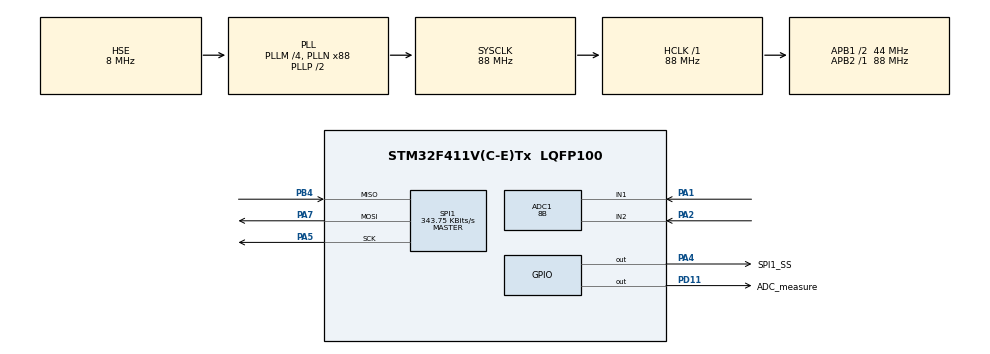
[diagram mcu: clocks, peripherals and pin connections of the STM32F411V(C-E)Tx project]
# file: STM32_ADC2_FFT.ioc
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ADC1.Channel-0\#ChannelRegularConversion=ADC_CHANNEL_1
ADC1.Channel-1\#ChannelRegularConversion=ADC_CHANNEL_2
ADC1.ClockPrescaler=ADC_CLOCK_SYNC_PCLK_DIV4
ADC1.ContinuousConvMode=ENABLE
ADC1.DMAContinuousRequests=ENABLE
ADC1.EOCSelection=ADC_EOC_SINGLE_CONV
ADC1.EnableAnalogWatchDog=true
ADC1.HighThreshold=128
ADC1.ITMode=ENABLE
ADC1.NbrOfConversion=2
ADC1.NbrOfConversionFlag=1
ADC1.Rank-0\#ChannelRegularConversion=1
ADC1.Rank-1\#ChannelRegularConversion=2
ADC1.Resolution=ADC_RESOLUTION_8B
ADC1.SamplingTime-0\#ChannelRegularConversion=ADC_SAMPLETIME_3CYCLES
ADC1.SamplingTime-1\#ChannelRegularConversion=ADC_SAMPLETIME_3CYCLES
ADC1.ScanConvMode=ENABLE
ADC1.WatchdogChannel=ADC_CHANNEL_1
ADC1.master=1
Dma.ADC1.0.Direction=DMA_PERIPH_TO_MEMORY
Dma.ADC1.0.FIFOMode=DMA_FIFOMODE_DISABLE
Dma.ADC1.0.Instance=DMA2_Stream0
Dma.ADC1.0.MemDataAlignment=DMA_MDATAALIGN_BYTE
Dma.ADC1.0.MemInc=DMA_MINC_ENABLE
Dma.ADC1.0.Mode=DMA_CIRCULAR
Dma.ADC1.0.PeriphDataAlignment=DMA_PDATAALIGN_BYTE
Dma.ADC1.0.PeriphInc=DMA_PINC_DISABLE
Dma.ADC1.0.Priority=DMA_PRIORITY_VERY_HIGH
Dma.Request0=ADC1
Mcu.Family=STM32F4
Mcu.Name=STM32F411V(C-E)Tx
Mcu.Package=LQFP100
NVIC.ADC_IRQn=true\:0\:0\:false\:false\:true\:true\:true\:true
NVIC.DMA2_Stream0_IRQn=true\:1\:0\:true\:false\:true\:false\:true\:true
NVIC.PriorityGroup=NVIC_PRIORITYGROUP_1
NVIC.SPI1_IRQn=true\:1\:0\:true\:false\:true\:true\:true\:true
NVIC.TIM1_BRK_TIM9_IRQn=true\:1\:0\:true\:false\:true\:true\:true\:true
PA1.Signal=ADCx_IN1
PA13.Mode=Serial_Wire
PA13.Signal=SYS_JTMS-SWDIO
PA14.Mode=Serial_Wire
PA14.Signal=SYS_JTCK-SWCLK
PA2.Signal=ADCx_IN2
PA4.GPIO_Label=SPI1_SS
PA4.GPIO_Speed=GPIO_SPEED_FREQ_VERY_HIGH
PA4.PinState=GPIO_PIN_SET
PA4.Signal=GPIO_Output
PA5.Mode=Full_Duplex_Master
PA5.Signal=SPI1_SCK
PA7.Mode=Full_Duplex_Master
PA7.Signal=SPI1_MOSI
PB4.Mode=Full_Duplex_Master
PB4.Signal=SPI1_MISO
PD11.GPIO_Label=ADC_measure
PD11.GPIO_Speed=GPIO_SPEED_FREQ_VERY_HIGH
PD11.Signal=GPIO_Output
PH0\ -\ OSC_IN.Mode=HSE-External-Oscillator
PH0\ -\ OSC_IN.Signal=RCC_OSC_IN
PH1\ -\ OSC_OUT.Mode=HSE-External-Oscillator
PH1\ -\ OSC_OUT.Signal=RCC_OSC_OUT
ProjectManager.HeapSize=0x200
ProjectManager.StackSize=0x400
ProjectManager.TargetToolchain=STM32CubeIDE
RCC.48MHZClocksFreq_Value=58666666.666666664
RCC.AHBFreq_Value=88000000
RCC.APB1CLKDivider=RCC_HCLK_DIV2
RCC.APB1Freq_Value=44000000
RCC.APB1TimFreq_Value=88000000
RCC.APB2Freq_Value=88000000
RCC.APB2TimFreq_Value=88000000
RCC.CortexFreq_Value=88000000
RCC.HCLKFreq_Value=88000000
RCC.HSE_VALUE=8000000
RCC.HSI_VALUE=16000000
RCC.LSE_VALUE=32768
RCC.PLLI2SM=5
RCC.PLLI2SN=200
RCC.PLLM=4
RCC.PLLN=88
RCC.PLLQ=3
RCC.PLLSourceVirtual=RCC_PLLSOURCE_HSE
RCC.SYSCLKFreq_VALUE=88000000
RCC.SYSCLKSource=RCC_SYSCLKSOURCE_PLLCLK
RCC.VCOOutputFreq_Value=176000000
SH.ADCx_IN1.0=ADC1_IN1,IN1
SH.ADCx_IN2.0=ADC1_IN2,IN2
SPI1.BaudRatePrescaler=SPI_BAUDRATEPRESCALER_256
SPI1.CLKPhase=SPI_PHASE_2EDGE
SPI1.CalculateBaudRate=343.75 KBits/s
SPI1.Direction=SPI_DIRECTION_2LINES
SPI1.Mode=SPI_MODE_MASTER
SPI1.VirtualType=VM_MASTER
STMicroelectronics.X-CUBE-ALGOBUILD.1.3.0.LibraryCcDSPOoLibraryJjDSPOoLibrary=true
TIM9.Period=60000 -1
TIM9.Prescaler=320 - 1
VP_STMicroelectronics.X-CUBE-ALGOBUILD_VS_DSPOoLibraryJjLibrary_1.3.0_1.3.0.Mode=DSPOoLibraryJjLibrary
VP_TIM9_VS_ClockSourceINT.Mode=Internal
board=STM32F411E-DISCO

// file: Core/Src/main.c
/* USER CODE BEGIN Header */
/**
  ******************************************************************************
  * @file           : main.c
  * @brief          : Main program body
  ******************************************************************************
  * @attention
  *
  * Copyright (c) 2023 STMicroelectronics.
  * All rights reserved.
  *
  * This software is licensed under terms that can be found in the LICENSE file
  * in the root directory of this software component.
  * If no LICENSE file comes with this software, it is provided AS-IS.
  *
  ******************************************************************************
  */
/* USER CODE END Header */
#include "main.h"

/* USER CODE BEGIN Includes */

#include "processing.h"
#include "settings.h"
#include "arm_math.h"
/* USER CODE END Includes */

ADC_HandleTypeDef hadc1;
DMA_HandleTypeDef hdma_adc1;

SPI_HandleTypeDef hspi1;

TIM_HandleTypeDef htim9;

/* USER CODE BEGIN PV */

volatile uint8_t ADC_DMA_Buf[DMA_BUFFER_SIZE];
volatile uint8_t processReadyFlag = 0;

/* USER CODE END PV */

void DoFFT();
void SystemClock_Config(void);
static void MX_GPIO_Init(void);
static void MX_DMA_Init(void);
static void MX_ADC1_Init(void);
static void MX_SPI1_Init(void);
static void MX_TIM9_Init(void);

int main(void)
{

  /* MCU Configuration--------------------------------------------------------*/

  /* Reset of all peripherals, Initializes the Flash interface and the Systick. */
  HAL_Init();

  /* Configure the system clock */
  SystemClock_Config();

  /* Initialize all configured peripherals */
  MX_GPIO_Init();
  MX_DMA_Init();
  MX_ADC1_Init();
  MX_SPI1_Init();
  MX_TIM9_Init();
  /* USER CODE BEGIN 2 */

  //Start the timer
  //HAL_TIM_Base_Start_IT(&htim9);
  set_trigger_channel(1);
  set_trigger(&hadc1, RISING_EDGE, 50);
  update_settings();
  HAL_ADC_Start_DMA(&hadc1, ADC_DMA_Buf, DMA_BUFFER_SIZE);

  /* USER CODE END 2 */

  /* Infinite loop */
  /* USER CODE BEGIN WHILE */
  while (1)
  {

	 //if (processReadyFlag)
	 {
		  process_DMA_buf();
	 }

    /* USER CODE END WHILE */

  }
}

void SystemClock_Config(void)
{
  RCC_OscInitTypeDef RCC_OscInitStruct = {0};
  RCC_ClkInitTypeDef RCC_ClkInitStruct = {0};

  /** Configure the main internal regulator output voltage
  */
  __HAL_RCC_PWR_CLK_ENABLE();
  __HAL_PWR_VOLTAGESCALING_CONFIG(PWR_REGULATOR_VOLTAGE_SCALE1);

  /** Initializes the RCC Oscillators according to the specified parameters
  * in the RCC_OscInitTypeDef structure.
  */
  RCC_OscInitStruct.OscillatorType = RCC_OSCILLATORTYPE_HSE;
  RCC_OscInitStruct.HSEState = RCC_HSE_ON;
  RCC_OscInitStruct.PLL.PLLState = RCC_PLL_ON;
  RCC_OscInitStruct.PLL.PLLSource = RCC_PLLSOURCE_HSE;
  RCC_OscInitStruct.PLL.PLLM = 4;
  RCC_OscInitStruct.PLL.PLLN = 88;
  RCC_OscInitStruct.PLL.PLLP = RCC_PLLP_DIV2;
  RCC_OscInitStruct.PLL.PLLQ = 3;
  if (HAL_RCC_OscConfig(&RCC_OscInitStruct) != HAL_OK)
  {
    Error_Handler();
  }

  /** Initializes the CPU, AHB and APB buses clocks
  */
  RCC_ClkInitStruct.ClockType = RCC_CLOCKTYPE_HCLK|RCC_CLOCKTYPE_SYSCLK
                              |RCC_CLOCKTYPE_PCLK1|RCC_CLOCKTYPE_PCLK2;
  RCC_ClkInitStruct.SYSCLKSource = RCC_SYSCLKSOURCE_PLLCLK;
  RCC_ClkInitStruct.AHBCLKDivider = RCC_SYSCLK_DIV1;
  RCC_ClkInitStruct.APB1CLKDivider = RCC_HCLK_DIV2;
  RCC_ClkInitStruct.APB2CLKDivider = RCC_HCLK_DIV1;

  if (HAL_RCC_ClockConfig(&RCC_ClkInitStruct, FLASH_LATENCY_2) != HAL_OK)
  {
    Error_Handler();
  }
}

static void MX_ADC1_Init(void)
{

  ADC_AnalogWDGConfTypeDef AnalogWDGConfig = {0};
  ADC_ChannelConfTypeDef sConfig = {0};

  /** Configure the global features of the ADC (Clock, Resolution, Data Alignment and number of conversion)
  */
  hadc1.Instance = ADC1;
  hadc1.Init.ClockPrescaler = ADC_CLOCK_SYNC_PCLK_DIV4;
  hadc1.Init.Resolution = ADC_RESOLUTION_8B;
  hadc1.Init.ScanConvMode = ENABLE;
  hadc1.Init.ContinuousConvMode = ENABLE;
  hadc1.Init.DiscontinuousConvMode = DISABLE;
  hadc1.Init.ExternalTrigConvEdge = ADC_EXTERNALTRIGCONVEDGE_NONE;
  hadc1.Init.ExternalTrigConv = ADC_SOFTWARE_START;
  hadc1.Init.DataAlign = ADC_DATAALIGN_RIGHT;
  hadc1.Init.NbrOfConversion = 2;
  hadc1.Init.DMAContinuousRequests = ENABLE;
  hadc1.Init.EOCSelection = ADC_EOC_SINGLE_CONV;
  if (HAL_ADC_Init(&hadc1) != HAL_OK)
  {
    Error_Handler();
  }

  /** Configure the analog watchdog
  */
  AnalogWDGConfig.WatchdogMode = ADC_ANALOGWATCHDOG_SINGLE_REG;
  AnalogWDGConfig.HighThreshold = 128;
  AnalogWDGConfig.LowThreshold = 0;
  AnalogWDGConfig.Channel = ADC_CHANNEL_1;
  AnalogWDGConfig.ITMode = ENABLE;
  if (HAL_ADC_AnalogWDGConfig(&hadc1, &AnalogWDGConfig) != HAL_OK)
  {
    Error_Handler();
  }

  /** Configure for the selected ADC regular channel its corresponding rank in the sequencer and its sample time.
  */
  sConfig.Channel = ADC_CHANNEL_1;
  sConfig.Rank = 1;
  sConfig.SamplingTime = ADC_SAMPLETIME_3CYCLES;
  if (HAL_ADC_ConfigChannel(&hadc1, &sConfig) != HAL_OK)
  {
    Error_Handler();
  }

  /** Configure for the selected ADC regular channel its corresponding rank in the sequencer and its sample time.
  */
  sConfig.Channel = ADC_CHANNEL_2;
  sConfig.Rank = 2;
  if (HAL_ADC_ConfigChannel(&hadc1, &sConfig) != HAL_OK)
  {
    Error_Handler();
  }

}

static void MX_SPI1_Init(void)
{

  /* SPI1 parameter configuration*/
  hspi1.Instance = SPI1;
  hspi1.Init.Mode = SPI_MODE_MASTER;
  hspi1.Init.Direction = SPI_DIRECTION_2LINES;
  hspi1.Init.DataSize = SPI_DATASIZE_8BIT;
  hspi1.Init.CLKPolarity = SPI_POLARITY_LOW;
  hspi1.Init.CLKPhase = SPI_PHASE_2EDGE;
  hspi1.Init.NSS = SPI_NSS_SOFT;
  hspi1.Init.BaudRatePrescaler = SPI_BAUDRATEPRESCALER_256;
  hspi1.Init.FirstBit = SPI_FIRSTBIT_MSB;
  hspi1.Init.TIMode = SPI_TIMODE_DISABLE;
  hspi1.Init.CRCCalculation = SPI_CRCCALCULATION_DISABLE;
  hspi1.Init.CRCPolynomial = 10;
  if (HAL_SPI_Init(&hspi1) != HAL_OK)
  {
    Error_Handler();
  }

}

static void MX_TIM9_Init(void)
{

  TIM_ClockConfigTypeDef sClockSourceConfig = {0};

  htim9.Instance = TIM9;
  htim9.Init.Prescaler = 320 - 1;
  htim9.Init.CounterMode = TIM_COUNTERMODE_UP;
  htim9.Init.Period = 60000 -1;
  htim9.Init.ClockDivision = TIM_CLOCKDIVISION_DIV1;
  htim9.Init.AutoReloadPreload = TIM_AUTORELOAD_PRELOAD_DISABLE;
  if (HAL_TIM_Base_Init(&htim9) != HAL_OK)
  {
    Error_Handler();
  }
  sClockSourceConfig.ClockSource = TIM_CLOCKSOURCE_INTERNAL;
  if (HAL_TIM_ConfigClockSource(&htim9, &sClockSourceConfig) != HAL_OK)
  {
    Error_Handler();
  }

}

static void MX_DMA_Init(void)
{

  /* DMA controller clock enable */
  __HAL_RCC_DMA2_CLK_ENABLE();

  /* DMA interrupt init */
  /* DMA2_Stream0_IRQn interrupt configuration */
  HAL_NVIC_SetPriority(DMA2_Stream0_IRQn, 1, 0);
  HAL_NVIC_EnableIRQ(DMA2_Stream0_IRQn);

}

static void MX_GPIO_Init(void)
{
  GPIO_InitTypeDef GPIO_InitStruct = {0};

  /* GPIO Ports Clock Enable */
  __HAL_RCC_GPIOH_CLK_ENABLE();
  __HAL_RCC_GPIOA_CLK_ENABLE();
  __HAL_RCC_GPIOD_CLK_ENABLE();
  __HAL_RCC_GPIOB_CLK_ENABLE();

  /*Configure GPIO pin Output Level */
  HAL_GPIO_WritePin(SPI1_SS_GPIO_Port, SPI1_SS_Pin, GPIO_PIN_SET);

  /*Configure GPIO pin Output Level */
  HAL_GPIO_WritePin(ADC_measure_GPIO_Port, ADC_measure_Pin, GPIO_PIN_RESET);

  /*Configure GPIO pin : SPI1_SS_Pin */
  GPIO_InitStruct.Pin = SPI1_SS_Pin;
  GPIO_InitStruct.Mode = GPIO_MODE_OUTPUT_PP;
  GPIO_InitStruct.Pull = GPIO_NOPULL;
  GPIO_InitStruct.Speed = GPIO_SPEED_FREQ_VERY_HIGH;
  HAL_GPIO_Init(SPI1_SS_GPIO_Port, &GPIO_InitStruct);

  /*Configure GPIO pin : ADC_measure_Pin */
  GPIO_InitStruct.Pin = ADC_measure_Pin;
  GPIO_InitStruct.Mode = GPIO_MODE_OUTPUT_PP;
  GPIO_InitStruct.Pull = GPIO_NOPULL;
  GPIO_InitStruct.Speed = GPIO_SPEED_FREQ_VERY_HIGH;
  HAL_GPIO_Init(ADC_measure_GPIO_Port, &GPIO_InitStruct);

}

void Error_Handler(void)
{
  __disable_irq();
  while (1)
  {
  }
}
